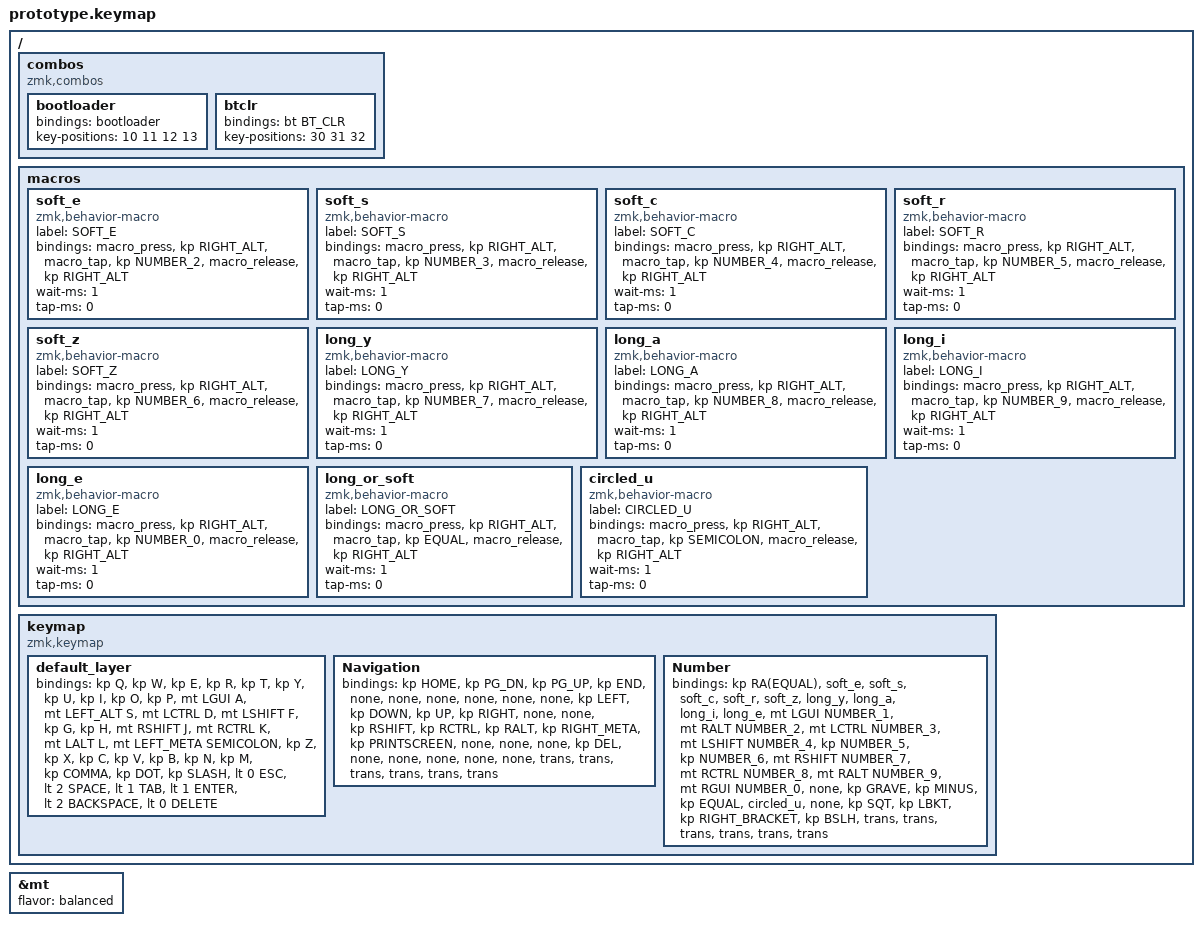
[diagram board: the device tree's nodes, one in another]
/*
 * Copyright (c) 2020 The ZMK Contributors
 *
 * SPDX-License-Identifier: MIT
 */

#include <behaviors.dtsi>
#include <dt-bindings/zmk/bt.h>
#include <dt-bindings/zmk/keys.h>

&mt {
    //  flavor = "tap-preferred";
    // tapping_term_ms = <200>;

    flavor = "balanced";
};

/ {
    combos {
        compatible = "zmk,combos";

        bootloader {
            bindings = <&bootloader>;
            key-positions = <10 11 12 13>;
        };

        btclr {
            bindings = <&bt BT_CLR>;
            key-positions = <30 31 32>;
        };
    };

    macros {
        soft_e: soft_e {
            compatible = "zmk,behavior-macro";
            label = "SOFT_E";
            #binding-cells = <0>;
            bindings =
                <&macro_press>,
                <&kp RIGHT_ALT>,
                <&macro_tap>,
                <&kp NUMBER_2>,
                <&macro_release>,
                <&kp RIGHT_ALT>;

            wait-ms = <1>;
            tap-ms = <0>;
        };

        soft_s: soft_s {
            compatible = "zmk,behavior-macro";
            label = "SOFT_S";
            #binding-cells = <0>;
            bindings =
                <&macro_press>,
                <&kp RIGHT_ALT>,
                <&macro_tap>,
                <&kp NUMBER_3>,
                <&macro_release>,
                <&kp RIGHT_ALT>;

            wait-ms = <1>;
            tap-ms = <0>;
        };

        soft_c: soft_c {
            compatible = "zmk,behavior-macro";
            label = "SOFT_C";
            #binding-cells = <0>;
            bindings =
                <&macro_press>,
                <&kp RIGHT_ALT>,
                <&macro_tap>,
                <&kp NUMBER_4>,
                <&macro_release>,
                <&kp RIGHT_ALT>;

            wait-ms = <1>;
            tap-ms = <0>;
        };

        soft_r: soft_r {
            compatible = "zmk,behavior-macro";
            label = "SOFT_R";
            #binding-cells = <0>;
            bindings =
                <&macro_press>,
                <&kp RIGHT_ALT>,
                <&macro_tap>,
                <&kp NUMBER_5>,
                <&macro_release>,
                <&kp RIGHT_ALT>;

            wait-ms = <1>;
            tap-ms = <0>;
        };

        soft_z: soft_z {
            compatible = "zmk,behavior-macro";
            label = "SOFT_Z";
            #binding-cells = <0>;
            bindings =
                <&macro_press>,
                <&kp RIGHT_ALT>,
                <&macro_tap>,
                <&kp NUMBER_6>,
                <&macro_release>,
                <&kp RIGHT_ALT>;

            wait-ms = <1>;
            tap-ms = <0>;
        };

        long_y: long_y {
            compatible = "zmk,behavior-macro";
            label = "LONG_Y";
            #binding-cells = <0>;
            bindings =
                <&macro_press>,
                <&kp RIGHT_ALT>,
                <&macro_tap>,
                <&kp NUMBER_7>,
                <&macro_release>,
                <&kp RIGHT_ALT>;

            wait-ms = <1>;
            tap-ms = <0>;
        };

        long_a: long_a {
            compatible = "zmk,behavior-macro";
            label = "LONG_A";
            #binding-cells = <0>;
            bindings =
                <&macro_press>,
                <&kp RIGHT_ALT>,
                <&macro_tap>,
                <&kp NUMBER_8>,
                <&macro_release>,
                <&kp RIGHT_ALT>;

            wait-ms = <1>;
            tap-ms = <0>;
        };

        long_i: long_i {
            compatible = "zmk,behavior-macro";
            label = "LONG_I";
            #binding-cells = <0>;
            bindings =
                <&macro_press>,
                <&kp RIGHT_ALT>,
                <&macro_tap>,
                <&kp NUMBER_9>,
                <&macro_release>,
                <&kp RIGHT_ALT>;

            wait-ms = <1>;
            tap-ms = <0>;
        };

        long_e: long_e {
            compatible = "zmk,behavior-macro";
            label = "LONG_E";
            #binding-cells = <0>;
            bindings =
                <&macro_press>,
                <&kp RIGHT_ALT>,
                <&macro_tap>,
                <&kp NUMBER_0>,
                <&macro_release>,
                <&kp RIGHT_ALT>;

            wait-ms = <1>;
            tap-ms = <0>;
        };

        long_or_soft: long_or_soft {
            compatible = "zmk,behavior-macro";
            label = "LONG_OR_SOFT";
            #binding-cells = <0>;
            bindings =
                <&macro_press>,
                <&kp RIGHT_ALT>,
                <&macro_tap>,
                <&kp EQUAL>,
                <&macro_release>,
                <&kp RIGHT_ALT>;

            wait-ms = <1>;
            tap-ms = <0>;
        };

        circled_u: circled_u {
            compatible = "zmk,behavior-macro";
            label = "CIRCLED_U";
            #binding-cells = <0>;
            bindings =
                <&macro_press>,
                <&kp RIGHT_ALT>,
                <&macro_tap>,
                <&kp SEMICOLON>,
                <&macro_release>,
                <&kp RIGHT_ALT>;

            wait-ms = <1>;
            tap-ms = <0>;
        };
    };

    keymap {
        compatible = "zmk,keymap";

        default_layer {
            bindings = <
&kp Q  &kp W  &kp E  &kp R  &kp T  &kp Y  &kp U  &kp I  &kp O  &kp P  &mt LGUI A  &mt LEFT_ALT S  &mt LCTRL D  &mt LSHIFT F  &kp G  &kp H  &mt RSHIFT J  &mt RCTRL K  &mt LALT L  &mt LEFT_META SEMICOLON  &kp Z  &kp X  &kp C  &kp V  &kp B  &kp N  &kp M  &kp COMMA  &kp DOT  &kp SLASH  &lt 0 ESC  &lt 2 SPACE  &lt 1 TAB  &lt 1 ENTER  &lt 2 BACKSPACE  &lt 0 DELETE
            >;
        };

        Navigation {
            bindings = <
&kp HOME  &kp PG_DN  &kp PG_UP  &kp END  &none  &none  &none  &none  &none  &none  &kp LEFT  &kp DOWN  &kp UP  &kp RIGHT  &none  &none  &kp RSHIFT  &kp RCTRL  &kp RALT  &kp RIGHT_META  &kp PRINTSCREEN  &none  &none  &none  &kp DEL  &none  &none  &none  &none  &none  &trans  &trans  &trans  &trans  &trans  &trans
            >;
        };

        Number {
            bindings = <
&kp RA(EQUAL)  &soft_e  &soft_s  &soft_c  &soft_r  &soft_z  &long_y  &long_a  &long_i  &long_e  &mt LGUI NUMBER_1  &mt RALT NUMBER_2  &mt LCTRL NUMBER_3  &mt LSHIFT NUMBER_4  &kp NUMBER_5  &kp NUMBER_6  &mt RSHIFT NUMBER_7  &mt RCTRL NUMBER_8  &mt RALT NUMBER_9  &mt RGUI NUMBER_0  &none  &kp GRAVE  &kp MINUS  &kp EQUAL  &circled_u  &none  &kp SQT  &kp LBKT  &kp RIGHT_BRACKET  &kp BSLH  &trans  &trans  &trans  &trans  &trans  &trans
            >;
        };
    };
};
